# MB9BF56xx register map
File version: 1.0
CPU: 
Registers are 8-bit, read-write, reset 0x0 unless marked. A register's access mark holds for its fields unless they carry their own. Offsets are from the block's base; [hi:lo] are bit positions; {n}, {i} and the like mark numbered series; 'fields as' and 'values as' point back to an identical list.

## DMAC — peripheral DMAC
Base 0x40060000
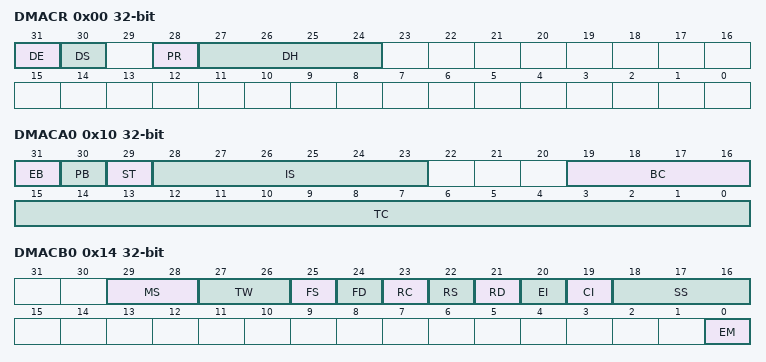
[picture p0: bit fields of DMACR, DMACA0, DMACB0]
0x00 DMACR 32-bit
  [31] DE, [30] DS, [28] PR, [27:24] DH
0x10 DMACA0 32-bit
  [31] EB, [30] PB, [29] ST, [28:23] IS, [19:16] BC, [15:0] TC
0x14 DMACB0 32-bit
  [29:28] MS, [27:26] TW, [25] FS, [24] FD, [23] RC, [22] RS, [21] RD, [20] EI, [19] CI, [18:16] SS, [0] EM
0x18 DMACSA0 32-bit
0x1C DMACDA0 32-bit
{0x10+0x10*i} DMACA{i} 32-bit reset not defined (i=1..7)
{0x14+0x10*i} DMACB{i} 32-bit reset not defined (i=1..7)
{0x18+0x10*i} DMACSA{i} 32-bit reset not defined (i=1..7)
{0x1C+0x10*i} DMACDA{i} 32-bit reset not defined (i=1..7)

## DSTC — peripheral DSTC
Base 0x40061000
0x00 DESTP 32-bit
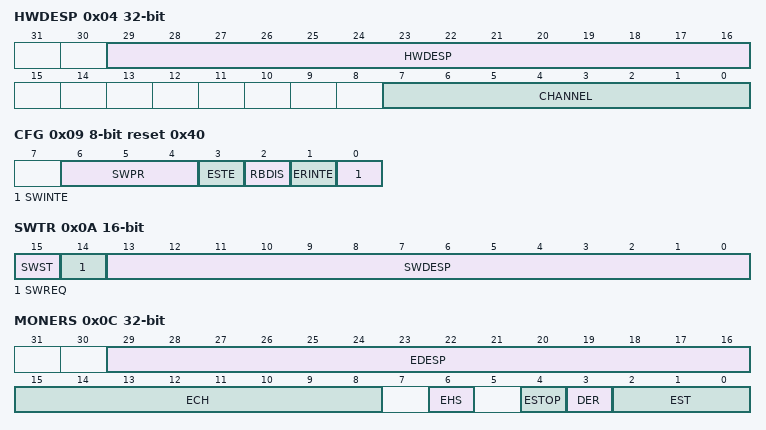
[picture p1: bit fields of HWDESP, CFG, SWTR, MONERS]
0x04 HWDESP 32-bit
  [29:16] HWDESP, [7:0] CHANNEL
0x08 CMD reset 0x1
0x09 CFG reset 0x40
  [6:4] SWPR, [3] ESTE, [2] RBDIS, [1] ERINTE, [0] SWINTE
0x0A SWTR 16-bit
  [15] SWST ro, [14] SWREQ ro, [13:0] SWDESP
0x0C MONERS 32-bit
  [29:16] EDESP ro, [15:8] ECH ro, [6] EHS ro, [4] ESTOP ro, [3] DER ro, [2:0] EST ro
0x10 DREQENB0 32-bit
{0x10+4i} DREQENB{i} 32-bit reset not defined (i=1..7)
0x30 HWINT0 32-bit
{0x30+4i} HWINT{i} 32-bit reset not defined (i=1..7)
0x70 DQMSK0 32-bit
{0x70+4i} DQMSK{i} 32-bit reset not defined (i=1..7)
0x90 DQMSKCLR0 32-bit
{0x90+4i} DQMSKCLR{i} 32-bit reset not defined (i=1..7)

## CANPRES — peripheral CANPRES
Base 0x40037000
0x00 CANPRE reset 0xB
  [3:0] CANPRE

## CAN0 — peripheral CAN0
Base 0x40062000
Same registers: CAN1 0x40063000
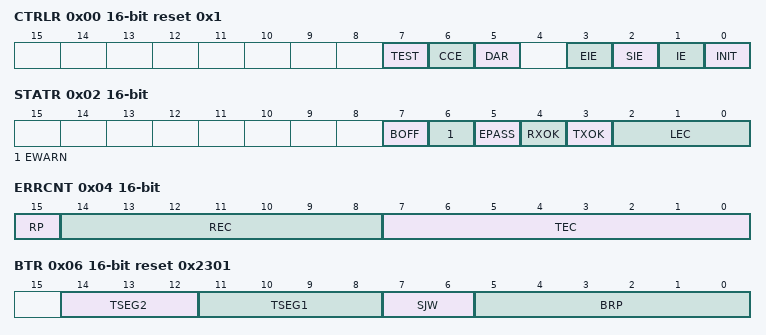
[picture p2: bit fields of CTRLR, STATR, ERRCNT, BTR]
0x00 CTRLR 16-bit reset 0x1
  [7] TEST, [6] CCE, [5] DAR, [3] EIE, [2] SIE, [1] IE, [0] INIT
0x02 STATR 16-bit
  [7] BOFF ro, [6] EWARN ro, [5] EPASS ro, [4] RXOK, [3] TXOK, [2:0] LEC
0x04 ERRCNT 16-bit ro reset not defined
  [15] RP, [14:8] REC, [7:0] TEC
0x06 BTR 16-bit reset 0x2301
  [14:12] TSEG2, [11:8] TSEG1, [7:6] SJW, [5:0] BRP
0x08 INTR 16-bit ro
  [15:0] INTID
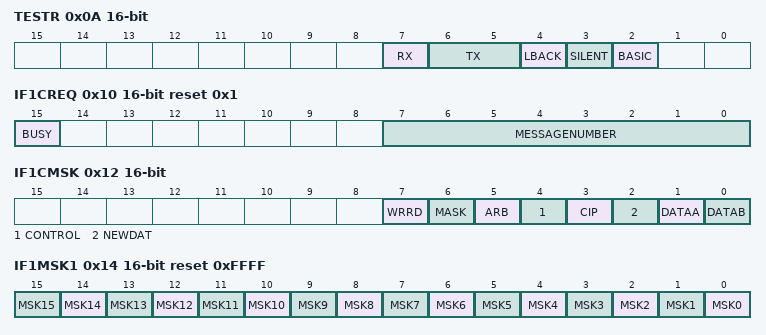
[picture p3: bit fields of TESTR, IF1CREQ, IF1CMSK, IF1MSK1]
0x0A TESTR 16-bit (reset mask 0xF4)
  [7] RX ro, [6:5] TX, [4] LBACK, [3] SILENT, [2] BASIC
0x0C BRPER 16-bit
  [3:0] BRPE
0x10 IF1CREQ 16-bit reset 0x1
  [15] BUSY, [7:0] MESSAGENUMBER
0x12 IF1CMSK 16-bit
  [7] WRRD, [6] MASK, [5] ARB, [4] CONTROL, [3] CIP, [2] NEWDAT, [1] DATAA, [0] DATAB
0x14 IF1MSK1 16-bit reset 0xFFFF
  [n] MSK{n} (n=0..15)
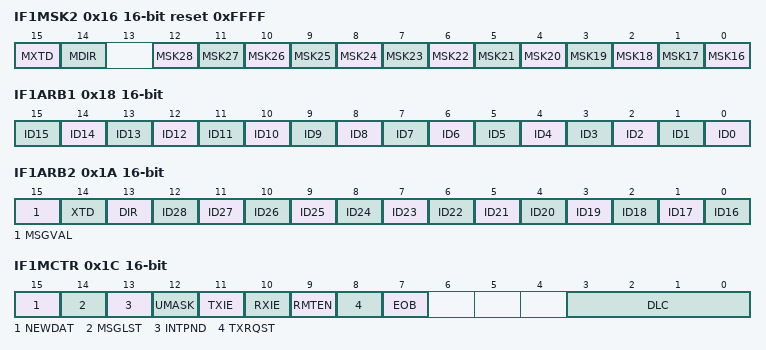
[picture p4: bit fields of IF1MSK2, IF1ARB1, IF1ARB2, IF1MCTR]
0x16 IF1MSK2 16-bit reset 0xFFFF
  [15] MXTD, [14] MDIR, [n-16] MSK{n} (n=16..28)
0x18 IF1ARB1 16-bit
  [n] ID{n} (n=0..15)
0x1A IF1ARB2 16-bit
  [15] MSGVAL, [14] XTD, [13] DIR, [n-16] ID{n} (n=16..28)
0x1C IF1MCTR 16-bit
  [15] NEWDAT, [14] MSGLST, [13] INTPND, [12] UMASK, [11] TXIE, [10] RXIE, [9] RMTEN, [8] TXRQST, [7] EOB, [3:0] DLC
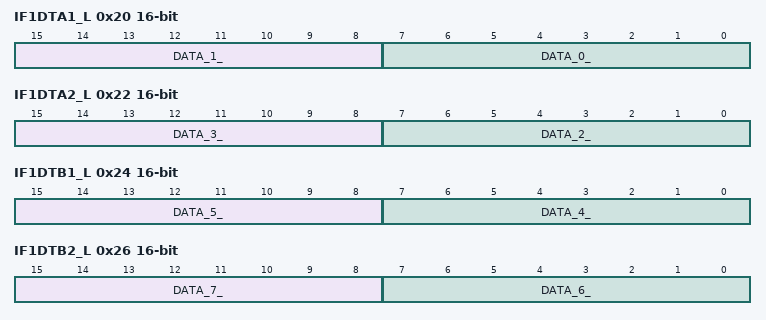
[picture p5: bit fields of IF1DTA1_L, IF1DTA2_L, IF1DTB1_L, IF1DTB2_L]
0x20 IF1DTA1_L 16-bit (reset mask 0xFF8F)
  [15:8] DATA_1_, [7:0] DATA_0_
0x22 IF1DTA2_L 16-bit
  [15:8] DATA_3_, [7:0] DATA_2_
0x24 IF1DTB1_L 16-bit
  [15:8] DATA_5_, [7:0] DATA_4_
0x26 IF1DTB2_L 16-bit
  [15:8] DATA_7_, [7:0] DATA_6_
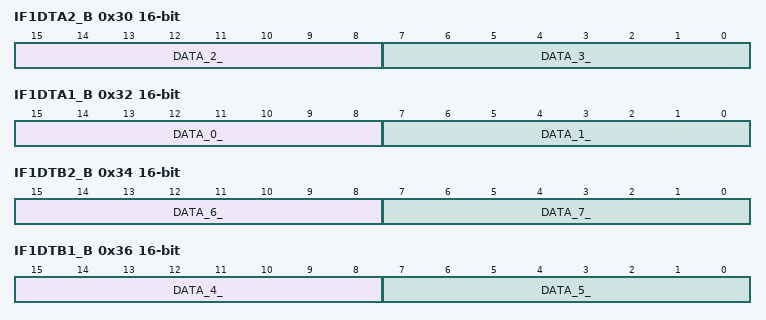
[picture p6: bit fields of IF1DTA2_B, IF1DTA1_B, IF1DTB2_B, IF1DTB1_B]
0x30 IF1DTA2_B 16-bit
  [15:8] DATA_2_, [7:0] DATA_3_
0x32 IF1DTA1_B 16-bit
  [15:8] DATA_0_, [7:0] DATA_1_
0x34 IF1DTB2_B 16-bit
  [15:8] DATA_6_, [7:0] DATA_7_
0x36 IF1DTB1_B 16-bit
  [15:8] DATA_4_, [7:0] DATA_5_
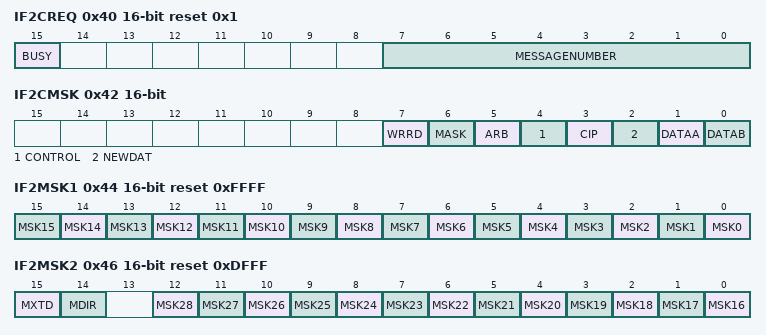
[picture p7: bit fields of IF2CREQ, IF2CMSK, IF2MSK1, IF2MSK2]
0x40 IF2CREQ 16-bit reset 0x1
  [15] BUSY, [7:0] MESSAGENUMBER
0x42 IF2CMSK 16-bit
  fields as IF1CMSK
0x44 IF2MSK1 16-bit reset 0xFFFF
  [n] MSK{n} (n=0..15)
0x46 IF2MSK2 16-bit reset 0xDFFF
  [15] MXTD, [14] MDIR, [n-16] MSK{n} (n=16..28)
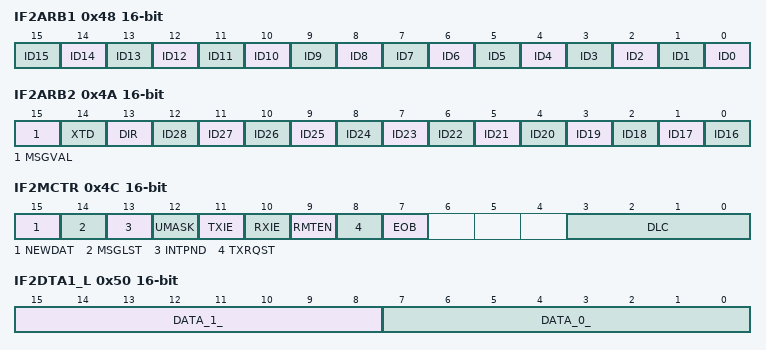
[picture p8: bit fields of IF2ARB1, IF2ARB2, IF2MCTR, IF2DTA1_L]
0x48 IF2ARB1 16-bit
  [n] ID{n} (n=0..15)
0x4A IF2ARB2 16-bit
  [15] MSGVAL, [14] XTD, [13] DIR, [n-16] ID{n} (n=16..28)
0x4C IF2MCTR 16-bit
  fields as IF1MCTR
0x50 IF2DTA1_L 16-bit
  [15:8] DATA_1_, [7:0] DATA_0_
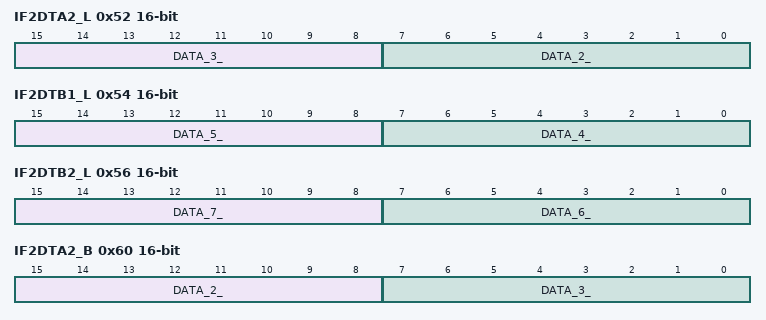
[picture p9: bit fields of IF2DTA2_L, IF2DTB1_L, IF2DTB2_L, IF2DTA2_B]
0x52 IF2DTA2_L 16-bit
  [15:8] DATA_3_, [7:0] DATA_2_
0x54 IF2DTB1_L 16-bit
  [15:8] DATA_5_, [7:0] DATA_4_
0x56 IF2DTB2_L 16-bit
  [15:8] DATA_7_, [7:0] DATA_6_
0x60 IF2DTA2_B 16-bit
  [15:8] DATA_2_, [7:0] DATA_3_
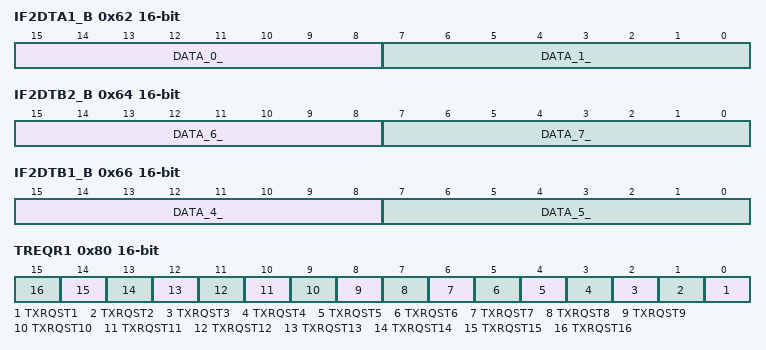
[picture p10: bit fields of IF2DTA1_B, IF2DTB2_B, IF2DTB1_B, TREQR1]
0x62 IF2DTA1_B 16-bit
  [15:8] DATA_0_, [7:0] DATA_1_
0x64 IF2DTB2_B 16-bit
  [15:8] DATA_6_, [7:0] DATA_7_
0x66 IF2DTB1_B 16-bit
  [15:8] DATA_4_, [7:0] DATA_5_
0x80 TREQR1 16-bit ro
  [n-1] TXRQST{n} (n=1..16)
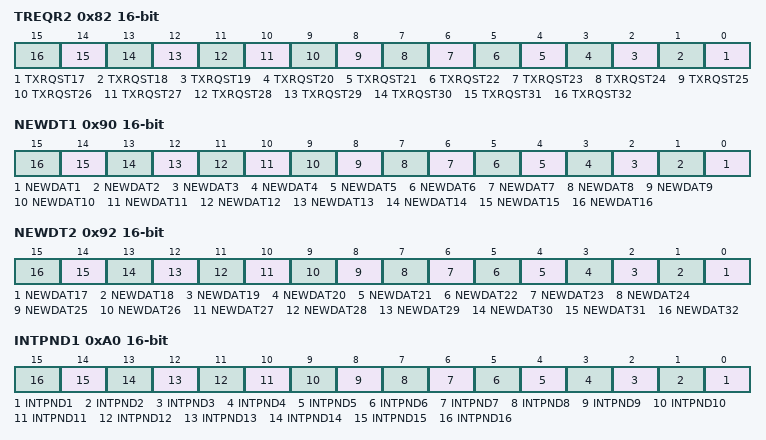
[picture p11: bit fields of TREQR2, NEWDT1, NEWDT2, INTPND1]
0x82 TREQR2 16-bit ro
  [n-17] TXRQST{n} (n=17..32)
0x90 NEWDT1 16-bit ro
  [n-1] NEWDAT{n} (n=1..16)
0x92 NEWDT2 16-bit ro
  [n-17] NEWDAT{n} (n=17..32)
0xA0 INTPND1 16-bit ro
  [n-1] INTPND{n} (n=1..16)
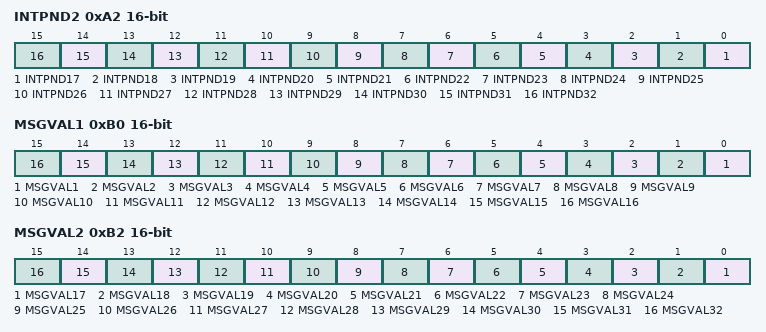
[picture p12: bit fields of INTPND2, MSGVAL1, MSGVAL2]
0xA2 INTPND2 16-bit ro
  [n-17] INTPND{n} (n=17..32)
0xB0 MSGVAL1 16-bit ro
  [n-1] MSGVAL{n} (n=1..16)
0xB2 MSGVAL2 16-bit ro
  [n-17] MSGVAL{n} (n=17..32)

## SDIF — peripheral SDIF
Base 0x4006E000
0x00 DUMMY 32-bit reset not defined
